# EOS-S3 register map
File version: 0.1
CPU: CM4 r0p1, selectable endian, MPU, FPU, 3 interrupt priority bits
Registers are 32-bit, read-write, reset 0x0 unless marked. A register's access mark holds for its fields unless they carry their own. Offsets are from the block's base; [hi:lo] are bit positions; {n}, {i} and the like mark numbered series; 'fields as' and 'values as' point back to an identical list.

## SDMA_Bridge — System Direct Memory Access Bridge
Base 0x4000D000
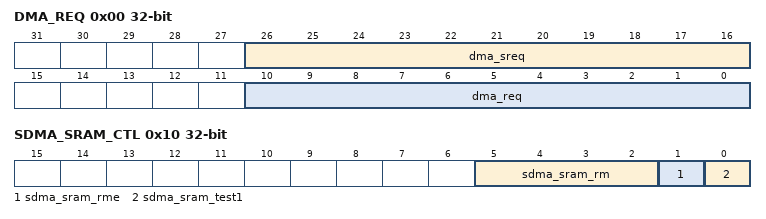
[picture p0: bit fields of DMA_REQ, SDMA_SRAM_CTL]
0x00 DMA_REQ — DMA request
  [26:16] dma_sreq wo — Single DMA request send to System DMA
  [10:0] dma_req wo — Burst DMA request send to System DMA
0x04 DMA_WAITONREQ_REG — DMA wait on request register
  [10:0] dma_waitonreq — waitonreq signal send to System DMA
0x08 DMA_ACTIVE_REG — dma_active signal status from System DMA
  [10:0] dma_active ro
0x0C SDMA_PWRD_CNT — sdma power down event threshold. If sdma stays in idle cycles longer than the threshold, sdma will be automaticlly put into power down to save power.
  [13:0] sdma_pwrdn_cnt
0x10 SDMA_SRAM_CTL — Control register for System DMA SRAM
  [5:2] sdma_sram_rm — SRAM adjust timing value
  [1] sdma_sram_rme — Set to enable SRAM timing adjust enable
  [0] sdma_sram_test1 — Set this bit to enable Test mode

## SDMA_SRAM — System DMA SRAM
Base 0x4000F000
0x00 SRC_DATA_END_PTR_CH0 — Primary pointer to the end address of the source data of channel 0
{0x4+0x10*i} DST_DATA_END_PTR_CH{i} (i=0..7) — Primary pointer to the end address of the destination data of channel {i}
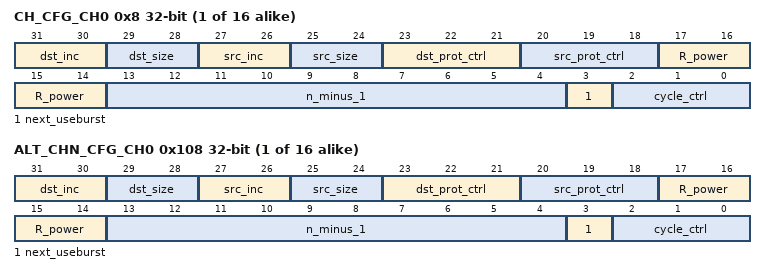
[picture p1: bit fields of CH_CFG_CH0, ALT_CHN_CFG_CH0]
{0x8+0x10*i} CH_CFG_CH{i} (i=0..15) — Primary configuration for channel {i}
  [31:30] dst_inc — Destination address increment
  [29:28] dst_size — Destination data size
  [27:26] src_inc — Source address increment
  [25:24] src_size — Source data size
  [23:21] dst_prot_ctrl — Set the bits to control the state of HPROT[3:1] when the controller writes the destination data
  [20:18] src_prot_ctrl — Set the bits to control the state of HPROT[3:1] when the controller reads the source data
  [17:14] R_power — Set these bits to control how many DMA transfers can occur before the controller rearbitrates
  [13:4] n_minus_1 — Prior to the DMA cycle commencing, these bits represent the total number of DMA transfers that the DMA cycle contains. You must set these bits according to the size of DMA cycle that you require.
  [3] next_useburst — Controls if the chnl_useburst_set [C] bit is set to a 1, when the controller is performing a peripheral scatter-gather and is completing a DMA cycle that uses the alternate data structure
  [2:0] cycle_ctrl — The operating mode of the DMA cycle
0x10 SRC_DATA_END_PTR_CH1 — Primary pointer to the end address of the source data of channel 1
0x20 SRC_DATA_END_PTR_CH2 — Primary pointer to the end address of the source data of channel 2
  [31:0] SRC_DATA_END_PTR_CH0
{0x0+0x10*i} SRC_DATA_END_PTR_CH{i} (i=3..15) — Primary pointer to the end address of the source data of channel {i}
0x84 DST_DATA_END_PTR_CH8 — Primary pointer to the end address of the destination data of channel 8
  [31:0] DST_DATA_END_PTR_CH8 — Primary pointer to the end address of the destination data of channel 0
0x94 DST_DATA_END_PTR_CH9 — Primary pointer to the end address of the destination data of channel 9
  [31:0] DST_DATA_END_PTR_CH9 — Primary pointer to the end address of the destination data of channel 0
{0x4+0x10*i} DST_DATA_END_PTR_CH{i} (i=10..15) — Primary pointer to the end address of the destination data of channel {i}
0x100 ALT_SRC_DATA_END_PTR_CH0 — Alternate pointer to the end address of the source data of channel 0
{0x104+0x10*i} ALT_DST_DATA_END_PTR_CH{i} (i=0..7) — Alternate pointer to the end address of the destination data of channel {i}
{0x108+0x10*i} ALT_CHN_CFG_CH{i} (i=0..15) — Primary configuration for channel {i}
  fields as CH_CFG_CH0
0x110 ALT_SRC_DATA_END_PTR_CH1 — Alternate pointer to the end address of the source data of channel 1
0x120 ALT_SRC_DATA_END_PTR_CH2 — Alternate pointer to the end address of the source data of channel 2
  [31:0] ALT_SRC_DATA_END_PTR_CH0
{0x100+0x10*i} ALT_SRC_DATA_END_PTR_CH{i} (i=3..15) — Alternate pointer to the end address of the source data of channel {i}
0x184 ALT_DST_DATA_END_PTR_CH8 — Alternate pointer to the end address of the destination data of channel 8
  [31:0] ALT_DST_DATA_END_PTR_CH8 — Alternate pointer to the end address of the destination data of channel 0
0x194 ALT_DST_DATA_END_PTR_CH9 — Alternate pointer to the end address of the destination data of channel 9
  [31:0] ALT_DST_DATA_END_PTR_CH9 — Alternate pointer to the end address of the destination data of channel 0
{0x104+0x10*i} ALT_DST_DATA_END_PTR_CH{i} (i=10..15) — Alternate pointer to the end address of the destination data of channel {i}

## TIMER — Timer peripheral
Base 0x40013000
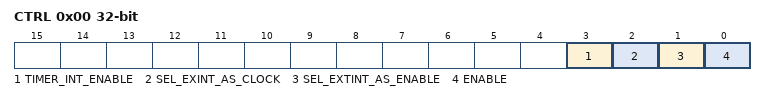
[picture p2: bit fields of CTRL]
0x00 CTRL — Timer control register
  [3] TIMER_INT_ENABLE — Timer interrupt enable
  [2] SEL_EXINT_AS_CLOCK — Select external input as clock
  [1] SEL_EXTINT_AS_ENABLE — Select external input as enable
  [0] ENABLE
0x04 VALUE — Current Value
0x08 RELOAD — Reload value. A write to this register sets the current value
0x0C INTSTATUS_INTCLEAR — Timer interrupt. Write one to clear
  [0] INTSTATUS_INTCLEAR — Timer interrupt, Write one to clear
0xFD0 PID4 ro — Peripheral ID register 4: [7:4] Block count. [3:0] jep106_c_code.
  [7:0] PID — Peripheral ID
{0xFC0+4i} PID{i} ro (i=5..7) — Peripheral ID register {i}
  [7:0] PID — Peripheral ID
0xFE0 PID0 ro — Peripheral ID Register 0: [7:0] Part Number[7:0].
  [7:0] PID — Peripheral ID
0xFE4 PID1 ro — Peripheral ID register 1: [7:0] jep106_id_3_0. [3:0] Par number[11:8].
  [7:0] PID — Peripheral ID
0xFE8 PID2 ro — Peripheral ID register 2: [7:4] Revision. [3] jedec_used. [2:0] jep106_id_6_4.
  [7:0] PID — Peripheral ID
0xFEC PID3 ro — Peripheral ID register 3: [7:4] ECO revision number. [3:0] Customer modification number.
  [7:0] PID — Peripheral ID
{0xFF0+4i} CID{i} ro (i=0..3) — Component ID register {i}
  [7:0] PID — Component ID

## SCB_ACTRL — System control block ACTLR
Base 0xE000E008
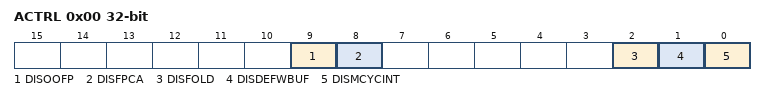
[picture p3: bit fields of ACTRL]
0x00 ACTRL — Auxiliary control register
  [9] DISOOFP, [8] DISFPCA, [2] DISFOLD, [1] DISDEFWBUF, [0] DISMCYCINT
